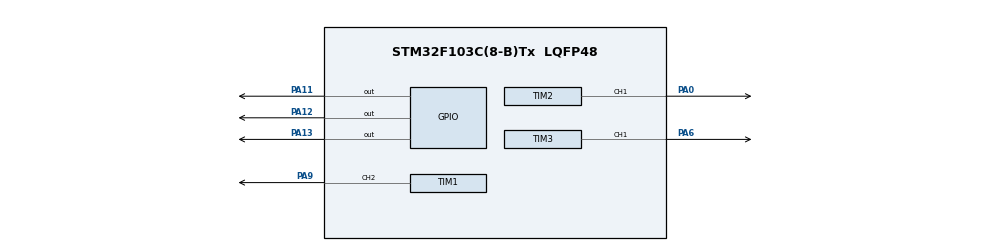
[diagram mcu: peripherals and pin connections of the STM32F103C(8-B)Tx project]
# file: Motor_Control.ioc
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Mcu.Family=STM32F1
Mcu.Name=STM32F103C(8-B)Tx
Mcu.Package=LQFP48
NVIC.PriorityGroup=NVIC_PRIORITYGROUP_4
PA0-WKUP.Signal=S_TIM2_CH1_ETR
PA11.Signal=GPIO_Output
PA12.Signal=GPIO_Output
PA13.Signal=GPIO_Output
PA6.Signal=S_TIM3_CH1
PA9.Signal=S_TIM1_CH2
ProjectManager.HeapSize=0x200
ProjectManager.StackSize=0x400
ProjectManager.TargetToolchain=STM32CubeIDE
RCC.APB1Freq_Value=8000000
RCC.APB2Freq_Value=8000000
SH.S_TIM1_CH2.0=TIM1_CH2,PWM Generation2 CH2
SH.S_TIM2_CH1_ETR.0=TIM2_CH1,PWM Generation1 CH1
SH.S_TIM3_CH1.0=TIM3_CH1,PWM Generation1 CH1
TIM1.Channel-PWM\ Generation2\ CH2=TIM_CHANNEL_2
TIM1.Period=999
TIM1.Prescaler=71
TIM2.Channel-PWM\ Generation1\ CH1=TIM_CHANNEL_1
TIM3.Channel-PWM\ Generation1\ CH1=TIM_CHANNEL_1
VP_SYS_VS_ND.Mode=No_Debug
board=custom

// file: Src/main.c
/* USER CODE BEGIN Header */
/**
  ******************************************************************************
  * @file           : main.c
  * @brief          : Main program body
  ******************************************************************************
  * @attention
  *
  * Copyright (c) 2025 STMicroelectronics.
  * All rights reserved.
  *
  * This software is licensed under terms that can be found in the LICENSE file
  * in the root directory of this software component.
  * If no LICENSE file comes with this software, it is provided AS-IS.
  *
  ******************************************************************************
  */
/* USER CODE END Header */
#include "main.h"

TIM_HandleTypeDef htim1;
TIM_HandleTypeDef htim2;
TIM_HandleTypeDef htim3;

void SystemClock_Config(void);
static void MX_GPIO_Init(void);
static void MX_TIM1_Init(void);
static void MX_TIM2_Init(void);
static void MX_TIM3_Init(void);

int main(void)
{

  /* MCU Configuration--------------------------------------------------------*/

  /* Reset of all peripherals, Initializes the Flash interface and the Systick. */
  HAL_Init();

  /* Configure the system clock */
  SystemClock_Config();

  /* Initialize all configured peripherals */
  MX_GPIO_Init();
  MX_TIM1_Init();
  MX_TIM2_Init();
  MX_TIM3_Init();
  /* USER CODE BEGIN 2 */
  HAL_TIM_PWM_Start(&htim1, TIM_CHANNEL_2);
  HAL_TIM_PWM_Start(&htim2, TIM_CHANNEL_1);
  HAL_TIM_PWM_Start(&htim3, TIM_CHANNEL_1);

  // Set initial duty cycle (0-999 for 0% to 100%)
  uint16_t speed_motor1 = 500; // 50% duty cycle
  uint16_t speed_motor2 = 750; // 75% duty cycle
  uint16_t speed_motor3 = 250; // 25% duty cycle

  __HAL_TIM_SET_COMPARE(&htim1, TIM_CHANNEL_2, speed_motor1);
  __HAL_TIM_SET_COMPARE(&htim2, TIM_CHANNEL_1, speed_motor2);
  __HAL_TIM_SET_COMPARE(&htim3, TIM_CHANNEL_1, speed_motor3);
  /* USER CODE END 2 */

  /* Infinite loop */
  while (1)
  {
	  //  Forward Motion (PWM Ramps Up)
	      HAL_GPIO_WritePin(GPIOA, GPIO_PIN_11, GPIO_PIN_SET); // Motor 1 Forward
	      HAL_GPIO_WritePin(GPIOA, GPIO_PIN_12, GPIO_PIN_SET); // Motor 2 Forward
	      HAL_GPIO_WritePin(GPIOA, GPIO_PIN_13, GPIO_PIN_SET); // Motor 3 Forward

	      for (uint16_t duty = 0; duty <= 999; duty += 50)
	      {
	          __HAL_TIM_SET_COMPARE(&htim1, TIM_CHANNEL_2, duty);
	          __HAL_TIM_SET_COMPARE(&htim2, TIM_CHANNEL_1, duty);
	          __HAL_TIM_SET_COMPARE(&htim3, TIM_CHANNEL_1, duty);
	          HAL_Delay(100);
	      }

	      HAL_Delay(1000); // Maintain at max speed for a while

	      //  Reverse Motion (PWM Ramps Down)
	      HAL_GPIO_WritePin(GPIOA, GPIO_PIN_11, GPIO_PIN_RESET); // Motor 1 Reverse
	      HAL_GPIO_WritePin(GPIOA, GPIO_PIN_12, GPIO_PIN_RESET); // Motor 2 Reverse
	      HAL_GPIO_WritePin(GPIOA, GPIO_PIN_13, GPIO_PIN_RESET); // Motor 3 Reverse

	      for (uint16_t duty = 999; duty > 0; duty -= 50)
	      {
	          __HAL_TIM_SET_COMPARE(&htim1, TIM_CHANNEL_2, duty);
	          __HAL_TIM_SET_COMPARE(&htim2, TIM_CHANNEL_1, duty);
	          __HAL_TIM_SET_COMPARE(&htim3, TIM_CHANNEL_1, duty);
	          HAL_Delay(100);
	      }

	      HAL_Delay(1000); // Maintain at min speed before switching back
	    }
  }

void SystemClock_Config(void)
{
  RCC_OscInitTypeDef RCC_OscInitStruct = {0};
  RCC_ClkInitTypeDef RCC_ClkInitStruct = {0};

  /** Initializes the RCC Oscillators according to the specified parameters
  * in the RCC_OscInitTypeDef structure.
  */
  RCC_OscInitStruct.OscillatorType = RCC_OSCILLATORTYPE_HSI;
  RCC_OscInitStruct.HSIState = RCC_HSI_ON;
  RCC_OscInitStruct.HSICalibrationValue = RCC_HSICALIBRATION_DEFAULT;
  RCC_OscInitStruct.PLL.PLLState = RCC_PLL_NONE;
  if (HAL_RCC_OscConfig(&RCC_OscInitStruct) != HAL_OK)
  {
    Error_Handler();
  }

  /** Initializes the CPU, AHB and APB buses clocks
  */
  RCC_ClkInitStruct.ClockType = RCC_CLOCKTYPE_HCLK|RCC_CLOCKTYPE_SYSCLK
                              |RCC_CLOCKTYPE_PCLK1|RCC_CLOCKTYPE_PCLK2;
  RCC_ClkInitStruct.SYSCLKSource = RCC_SYSCLKSOURCE_HSI;
  RCC_ClkInitStruct.AHBCLKDivider = RCC_SYSCLK_DIV1;
  RCC_ClkInitStruct.APB1CLKDivider = RCC_HCLK_DIV1;
  RCC_ClkInitStruct.APB2CLKDivider = RCC_HCLK_DIV1;

  if (HAL_RCC_ClockConfig(&RCC_ClkInitStruct, FLASH_LATENCY_0) != HAL_OK)
  {
    Error_Handler();
  }
}

static void MX_TIM1_Init(void)
{

  TIM_MasterConfigTypeDef sMasterConfig = {0};
  TIM_OC_InitTypeDef sConfigOC = {0};
  TIM_BreakDeadTimeConfigTypeDef sBreakDeadTimeConfig = {0};

  htim1.Instance = TIM1;
  htim1.Init.Prescaler = 71;
  htim1.Init.CounterMode = TIM_COUNTERMODE_UP;
  htim1.Init.Period = 999;
  htim1.Init.ClockDivision = TIM_CLOCKDIVISION_DIV1;
  htim1.Init.RepetitionCounter = 0;
  htim1.Init.AutoReloadPreload = TIM_AUTORELOAD_PRELOAD_DISABLE;
  if (HAL_TIM_PWM_Init(&htim1) != HAL_OK)
  {
    Error_Handler();
  }
  sMasterConfig.MasterOutputTrigger = TIM_TRGO_RESET;
  sMasterConfig.MasterSlaveMode = TIM_MASTERSLAVEMODE_DISABLE;
  if (HAL_TIMEx_MasterConfigSynchronization(&htim1, &sMasterConfig) != HAL_OK)
  {
    Error_Handler();
  }
  sConfigOC.OCMode = TIM_OCMODE_PWM1;
  sConfigOC.Pulse = 0;
  sConfigOC.OCPolarity = TIM_OCPOLARITY_HIGH;
  sConfigOC.OCNPolarity = TIM_OCNPOLARITY_HIGH;
  sConfigOC.OCFastMode = TIM_OCFAST_DISABLE;
  sConfigOC.OCIdleState = TIM_OCIDLESTATE_RESET;
  sConfigOC.OCNIdleState = TIM_OCNIDLESTATE_RESET;
  if (HAL_TIM_PWM_ConfigChannel(&htim1, &sConfigOC, TIM_CHANNEL_2) != HAL_OK)
  {
    Error_Handler();
  }
  sBreakDeadTimeConfig.OffStateRunMode = TIM_OSSR_DISABLE;
  sBreakDeadTimeConfig.OffStateIDLEMode = TIM_OSSI_DISABLE;
  sBreakDeadTimeConfig.LockLevel = TIM_LOCKLEVEL_OFF;
  sBreakDeadTimeConfig.DeadTime = 0;
  sBreakDeadTimeConfig.BreakState = TIM_BREAK_DISABLE;
  sBreakDeadTimeConfig.BreakPolarity = TIM_BREAKPOLARITY_HIGH;
  sBreakDeadTimeConfig.AutomaticOutput = TIM_AUTOMATICOUTPUT_DISABLE;
  if (HAL_TIMEx_ConfigBreakDeadTime(&htim1, &sBreakDeadTimeConfig) != HAL_OK)
  {
    Error_Handler();
  }
  HAL_TIM_MspPostInit(&htim1);

}

static void MX_TIM2_Init(void)
{

  TIM_MasterConfigTypeDef sMasterConfig = {0};
  TIM_OC_InitTypeDef sConfigOC = {0};

  htim2.Instance = TIM2;
  htim2.Init.Prescaler = 71;
  htim2.Init.CounterMode = TIM_COUNTERMODE_UP;
  htim2.Init.Period = 999;
  htim2.Init.ClockDivision = TIM_CLOCKDIVISION_DIV1;
  htim2.Init.AutoReloadPreload = TIM_AUTORELOAD_PRELOAD_DISABLE;
  if (HAL_TIM_PWM_Init(&htim2) != HAL_OK)
  {
    Error_Handler();
  }
  sMasterConfig.MasterOutputTrigger = TIM_TRGO_RESET;
  sMasterConfig.MasterSlaveMode = TIM_MASTERSLAVEMODE_DISABLE;
  if (HAL_TIMEx_MasterConfigSynchronization(&htim2, &sMasterConfig) != HAL_OK)
  {
    Error_Handler();
  }
  sConfigOC.OCMode = TIM_OCMODE_PWM1;
  sConfigOC.Pulse = 0;
  sConfigOC.OCPolarity = TIM_OCPOLARITY_HIGH;
  sConfigOC.OCFastMode = TIM_OCFAST_DISABLE;
  if (HAL_TIM_PWM_ConfigChannel(&htim2, &sConfigOC, TIM_CHANNEL_1) != HAL_OK)
  {
    Error_Handler();
  }
  HAL_TIM_MspPostInit(&htim2);

}

static void MX_TIM3_Init(void)
{

  TIM_MasterConfigTypeDef sMasterConfig = {0};
  TIM_OC_InitTypeDef sConfigOC = {0};

  htim3.Instance = TIM3;
  htim3.Init.Prescaler = 71;
  htim3.Init.CounterMode = TIM_COUNTERMODE_UP;
  htim3.Init.Period = 999;
  htim3.Init.ClockDivision = TIM_CLOCKDIVISION_DIV1;
  htim3.Init.AutoReloadPreload = TIM_AUTORELOAD_PRELOAD_DISABLE;
  if (HAL_TIM_PWM_Init(&htim3) != HAL_OK)
  {
    Error_Handler();
  }
  sMasterConfig.MasterOutputTrigger = TIM_TRGO_RESET;
  sMasterConfig.MasterSlaveMode = TIM_MASTERSLAVEMODE_DISABLE;
  if (HAL_TIMEx_MasterConfigSynchronization(&htim3, &sMasterConfig) != HAL_OK)
  {
    Error_Handler();
  }
  sConfigOC.OCMode = TIM_OCMODE_PWM1;
  sConfigOC.Pulse = 0;
  sConfigOC.OCPolarity = TIM_OCPOLARITY_HIGH;
  sConfigOC.OCFastMode = TIM_OCFAST_DISABLE;
  if (HAL_TIM_PWM_ConfigChannel(&htim3, &sConfigOC, TIM_CHANNEL_1) != HAL_OK)
  {
    Error_Handler();
  }
  HAL_TIM_MspPostInit(&htim3);

}

static void MX_GPIO_Init(void)
{
  GPIO_InitTypeDef GPIO_InitStruct = {0};

  /* GPIO Ports Clock Enable */
  __HAL_RCC_GPIOA_CLK_ENABLE();

  /*Configure GPIO pin Output Level */
  HAL_GPIO_WritePin(GPIOA, GPIO_PIN_11|GPIO_PIN_12|GPIO_PIN_13, GPIO_PIN_RESET);

  /*Configure GPIO pins : PA11 PA12 PA13 */
  GPIO_InitStruct.Pin = GPIO_PIN_11|GPIO_PIN_12|GPIO_PIN_13;
  GPIO_InitStruct.Mode = GPIO_MODE_OUTPUT_PP;
  GPIO_InitStruct.Pull = GPIO_NOPULL;
  GPIO_InitStruct.Speed = GPIO_SPEED_FREQ_LOW;
  HAL_GPIO_Init(GPIOA, &GPIO_InitStruct);

}

void Error_Handler(void)
{
  __disable_irq();
  while (1)
  {
  }
}
